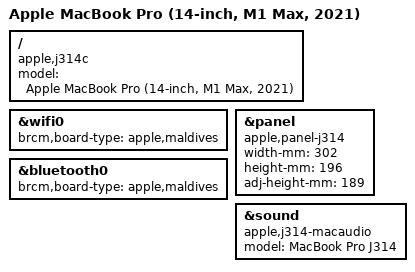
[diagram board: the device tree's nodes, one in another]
// SPDX-License-Identifier: GPL-2.0+ OR MIT
/*
 * MacBook Pro (14-inch, M1 Max, 2021)
 *
 * target-type: J314c
 *
 * Copyright The Asahi Linux Contributors
 */

/dts-v1/;

#include "t6001.dtsi"
#include "t600x-j314-j316.dtsi"

/ {
	compatible = "apple,j314c", "apple,t6001", "apple,arm-platform";
	model = "Apple MacBook Pro (14-inch, M1 Max, 2021)";
};

&wifi0 {
	brcm,board-type = "apple,maldives";
};

&bluetooth0 {
	brcm,board-type = "apple,maldives";
};

&panel {
	compatible = "apple,panel-j314", "apple,panel-mini-led", "apple,panel";
	width-mm = <302>;
	height-mm = <196>;
	adj-height-mm = <189>;
};

&sound {
	compatible = "apple,j314-macaudio", "apple,macaudio";
	model = "MacBook Pro J314";
};
